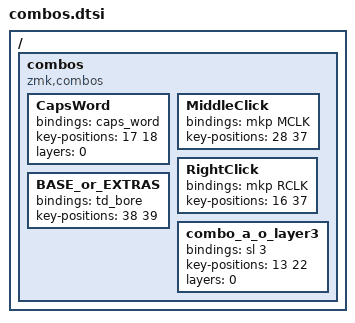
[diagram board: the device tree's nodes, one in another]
/ {
    combos {
        compatible = "zmk,combos";

        CapsWord {
            bindings = <&caps_word>;
            key-positions = <17 18>;
            layers = <0>;
        };

        MiddleClick {
            bindings = <&mkp MCLK>;
            key-positions = <28 37>;
        };

        RightClick {
            bindings = <&mkp RCLK>;
            key-positions = <16 37>;
        };

        BASE_or_EXTRAS {
            bindings = <&td_bore>;
            key-positions = <38 39>;
        };

        combo_a_o_layer3 {
            bindings = <&sl 3>;
            key-positions = <13 22>;
            layers = <0>;
        };
    };
};
